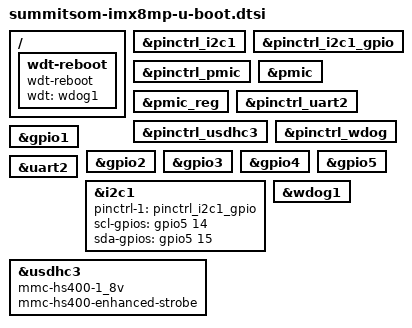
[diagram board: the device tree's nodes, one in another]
// SPDX-License-Identifier: LicenseRef-Ezurio-Clause
/*
 * Copyright 2021 Ezurio
 */

#include "imx8mp-u-boot.dtsi"

/ {
	wdt-reboot {
		compatible = "wdt-reboot";
		wdt = <&wdog1>;
		bootph-pre-ram;
	};
};

&pinctrl_i2c1 {
	bootph-all;
};

&pinctrl_i2c1_gpio {
	bootph-all;
};

&pinctrl_pmic {
	bootph-all;
};

&pmic {
	bootph-all;
};

&pmic_reg {
	bootph-all;
};

&pinctrl_uart2 {
	bootph-pre-ram;
};

&pinctrl_usdhc3 {
	bootph-pre-ram;
};

&pinctrl_wdog {
	bootph-pre-ram;
};

&gpio1 {
	bootph-pre-ram;
};

&gpio2 {
	bootph-pre-ram;
};

&gpio3 {
	bootph-pre-ram;
};

&gpio4 {
	bootph-pre-ram;
};

&gpio5 {
	bootph-pre-ram;
};

&uart2 {
	bootph-pre-ram;
};

&i2c1 {
	bootph-all;

	pinctrl-names = "default", "gpio";
	pinctrl-1 = <&pinctrl_i2c1_gpio>;
	scl-gpios = <&gpio5 14 (GPIO_ACTIVE_HIGH | GPIO_OPEN_DRAIN)>;
	sda-gpios = <&gpio5 15 (GPIO_ACTIVE_HIGH | GPIO_OPEN_DRAIN)>;
};

&usdhc3 {
	mmc-hs400-1_8v;
	mmc-hs400-enhanced-strobe;
};

&wdog1 {
	bootph-pre-ram;
};
